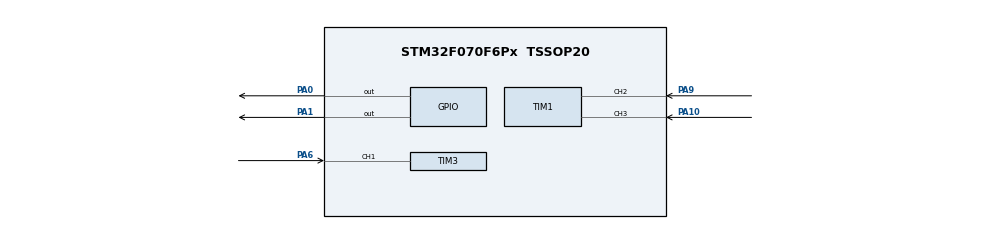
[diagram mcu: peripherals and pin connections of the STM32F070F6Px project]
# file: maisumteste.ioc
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Mcu.Family=STM32F0
Mcu.Name=STM32F070F6Px
Mcu.Package=TSSOP20
NVIC.TIM1_BRK_UP_TRG_COM_IRQn=true\:0\:0\:false\:false\:true\:true\:true\:true
NVIC.TIM1_CC_IRQn=true\:0\:0\:false\:false\:true\:true\:true\:true
NVIC.TIM3_IRQn=true\:0\:0\:false\:false\:true\:true\:true\:true
PA0.Signal=GPIO_Output
PA1.Signal=GPIO_Output
PA10.Signal=S_TIM1_CH3
PA13.Mode=Serial_Wire
PA13.Signal=SYS_SWDIO
PA14.Mode=Serial_Wire
PA14.Signal=SYS_SWCLK
PA6.Signal=S_TIM3_CH1
PA9.Signal=S_TIM1_CH2
PF0-OSC_IN.Mode=HSE-External-Oscillator
PF0-OSC_IN.Signal=RCC_OSC_IN
PF1-OSC_OUT.Mode=HSE-External-Oscillator
PF1-OSC_OUT.Signal=RCC_OSC_OUT
ProjectManager.HeapSize=0x200
ProjectManager.StackSize=0x400
ProjectManager.TargetToolchain=STM32CubeIDE
SH.S_TIM1_CH2.0=TIM1_CH2,Input_Capture2_from_TI2
SH.S_TIM1_CH3.0=TIM1_CH3,Input_Capture3_from_TI3
SH.S_TIM3_CH1.0=TIM3_CH1,Input_Capture1_from_TI1
TIM1.Channel-Input_Capture2_from_TI2=TIM_CHANNEL_2
TIM1.Channel-Input_Capture3_from_TI3=TIM_CHANNEL_3
TIM1.ICPolarity_CH3=TIM_INPUTCHANNELPOLARITY_FALLING
TIM3.Channel-Input_Capture1_from_TI1=TIM_CHANNEL_1
TIM3.Period=1000
TIM3.Prescaler=800
TIM3.TIM_MasterOutputTrigger=TIM_TRGO_RESET
VP_TIM3_VS_ClockSourceINT.Mode=Internal
board=custom

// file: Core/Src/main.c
/* USER CODE BEGIN Header */
/**
  ******************************************************************************
  * @file           : main.c
  * @brief          : Main program body
  ******************************************************************************
  * @attention
  *
  * Copyright (c) 2022 STMicroelectronics.
  * All rights reserved.
  *
  * This software is licensed under terms that can be found in the LICENSE file
  * in the root directory of this software component.
  * If no LICENSE file comes with this software, it is provided AS-IS.
  *
  ******************************************************************************
  */
/* USER CODE END Header */
#include "main.h"

TIM_HandleTypeDef htim1;
TIM_HandleTypeDef htim3;
long uss1_delay = 0;

void SystemClock_Config(void);
static void MX_GPIO_Init(void);
static void MX_TIM3_Init(void);
static void MX_TIM1_Init(void);
/* USER CODE BEGIN PFP */
void HAL_TIM_IC_CaptureCallback(TIM_HandleTypeDef *htim);
void HAL_TIM_PeriodElapsedCallback(TIM_HandleTypeDef *htim);
uint32_t getUs(void);
void Delay_Us(uint32_t micros);
/* USER CODE END PFP */

int main(void)
{

  /* MCU Configuration--------------------------------------------------------*/

  /* Reset of all peripherals, Initializes the Flash interface and the Systick. */
  HAL_Init();

  /* Configure the system clock */
  SystemClock_Config();

  /* Initialize all configured peripherals */
  MX_GPIO_Init();
  MX_TIM3_Init();
  MX_TIM1_Init();
  /* USER CODE BEGIN 2 */
  HAL_TIM_Base_Start_IT(&htim3);//clock do trigger
  HAL_TIM_IC_Start_IT(&htim1, TIM_CHANNEL_2);//pino de subida
  HAL_TIM_IC_Start_IT(&htim1, TIM_CHANNEL_3);//pino de descida
  /* USER CODE END 2 */

  /* Infinite loop */
  while (1)
  {
	  uss1_delay=HAL_TIM_ReadCapturedValue(&htim1, TIM_CHANNEL_3) - HAL_TIM_ReadCapturedValue(&htim1, TIM_CHANNEL_2);
	  HAL_Delay(90);
	  	  if (uss1_delay>600){
	  		  	HAL_GPIO_WritePin(GPIOA,GPIO_PIN_1,GPIO_PIN_SET);
	  	  		HAL_Delay(100);
	  	  		HAL_GPIO_WritePin(GPIOA,GPIO_PIN_1,GPIO_PIN_RESET);
	  	  		HAL_Delay(1000);
	  	  	}
	  	  else if (uss1_delay<=600 && uss1_delay>400){
	  	  	  	HAL_GPIO_WritePin(GPIOA,GPIO_PIN_1,GPIO_PIN_SET);
	  	  	  	HAL_Delay(100);
	  	  	  	HAL_GPIO_WritePin(GPIOA,GPIO_PIN_1,GPIO_PIN_RESET);
	  	  	  	HAL_Delay(500);
	  	  	}
	  	  else if (uss1_delay<=400 && uss1_delay>200){
	  	  		HAL_GPIO_WritePin(GPIOA,GPIO_PIN_1,GPIO_PIN_SET);
	  	  		HAL_Delay(100);
	  	  		HAL_GPIO_WritePin(GPIOA,GPIO_PIN_1,GPIO_PIN_RESET);
	  	  		HAL_Delay(200);
	  	  	}
	  	  else if (uss1_delay<=200 && uss1_delay>100){
	  	  		HAL_GPIO_WritePin(GPIOA,GPIO_PIN_1,GPIO_PIN_SET);
	  	  		HAL_Delay(100);
	  	  		HAL_GPIO_WritePin(GPIOA,GPIO_PIN_1,GPIO_PIN_RESET);
	  	    }
	  	  else if (uss1_delay<=100){
	  			HAL_GPIO_WritePin(GPIOA,GPIO_PIN_1,GPIO_PIN_SET);
	  		}
  }
}

void SystemClock_Config(void)
{
  RCC_OscInitTypeDef RCC_OscInitStruct = {0};
  RCC_ClkInitTypeDef RCC_ClkInitStruct = {0};

  /** Initializes the RCC Oscillators according to the specified parameters
  * in the RCC_OscInitTypeDef structure.
  */
  RCC_OscInitStruct.OscillatorType = RCC_OSCILLATORTYPE_HSI;
  RCC_OscInitStruct.HSIState = RCC_HSI_ON;
  RCC_OscInitStruct.HSICalibrationValue = RCC_HSICALIBRATION_DEFAULT;
  RCC_OscInitStruct.PLL.PLLState = RCC_PLL_NONE;
  if (HAL_RCC_OscConfig(&RCC_OscInitStruct) != HAL_OK)
  {
    Error_Handler();
  }

  /** Initializes the CPU, AHB and APB buses clocks
  */
  RCC_ClkInitStruct.ClockType = RCC_CLOCKTYPE_HCLK|RCC_CLOCKTYPE_SYSCLK
                              |RCC_CLOCKTYPE_PCLK1;
  RCC_ClkInitStruct.SYSCLKSource = RCC_SYSCLKSOURCE_HSI;
  RCC_ClkInitStruct.AHBCLKDivider = RCC_SYSCLK_DIV1;
  RCC_ClkInitStruct.APB1CLKDivider = RCC_HCLK_DIV1;

  if (HAL_RCC_ClockConfig(&RCC_ClkInitStruct, FLASH_LATENCY_0) != HAL_OK)
  {
    Error_Handler();
  }
}

static void MX_TIM1_Init(void)
{

  TIM_MasterConfigTypeDef sMasterConfig = {0};
  TIM_IC_InitTypeDef sConfigIC = {0};

  htim1.Instance = TIM1;
  htim1.Init.Prescaler = 31;
  htim1.Init.CounterMode = TIM_COUNTERMODE_UP;
  htim1.Init.Period = 60000;
  htim1.Init.ClockDivision = TIM_CLOCKDIVISION_DIV1;
  htim1.Init.RepetitionCounter = 0;
  htim1.Init.AutoReloadPreload = TIM_AUTORELOAD_PRELOAD_DISABLE;
  if (HAL_TIM_IC_Init(&htim1) != HAL_OK)
  {
    Error_Handler();
  }
  sMasterConfig.MasterOutputTrigger = TIM_TRGO_RESET;
  sMasterConfig.MasterSlaveMode = TIM_MASTERSLAVEMODE_DISABLE;
  if (HAL_TIMEx_MasterConfigSynchronization(&htim1, &sMasterConfig) != HAL_OK)
  {
    Error_Handler();
  }
  sConfigIC.ICPolarity = TIM_INPUTCHANNELPOLARITY_RISING;
  sConfigIC.ICSelection = TIM_ICSELECTION_DIRECTTI;
  sConfigIC.ICPrescaler = TIM_ICPSC_DIV1;
  sConfigIC.ICFilter = 0;
  if (HAL_TIM_IC_ConfigChannel(&htim1, &sConfigIC, TIM_CHANNEL_2) != HAL_OK)
  {
    Error_Handler();
  }
  sConfigIC.ICPolarity = TIM_INPUTCHANNELPOLARITY_FALLING;
  if (HAL_TIM_IC_ConfigChannel(&htim1, &sConfigIC, TIM_CHANNEL_3) != HAL_OK)
  {
    Error_Handler();
  }

}

static void MX_TIM3_Init(void)
{

  TIM_ClockConfigTypeDef sClockSourceConfig = {0};
  TIM_MasterConfigTypeDef sMasterConfig = {0};
  TIM_IC_InitTypeDef sConfigIC = {0};

  htim3.Instance = TIM3;
  htim3.Init.Prescaler = 800;
  htim3.Init.CounterMode = TIM_COUNTERMODE_UP;
  htim3.Init.Period = 1000;
  htim3.Init.ClockDivision = TIM_CLOCKDIVISION_DIV1;
  htim3.Init.AutoReloadPreload = TIM_AUTORELOAD_PRELOAD_DISABLE;
  if (HAL_TIM_Base_Init(&htim3) != HAL_OK)
  {
    Error_Handler();
  }
  sClockSourceConfig.ClockSource = TIM_CLOCKSOURCE_INTERNAL;
  if (HAL_TIM_ConfigClockSource(&htim3, &sClockSourceConfig) != HAL_OK)
  {
    Error_Handler();
  }
  if (HAL_TIM_IC_Init(&htim3) != HAL_OK)
  {
    Error_Handler();
  }
  sMasterConfig.MasterOutputTrigger = TIM_TRGO_RESET;
  sMasterConfig.MasterSlaveMode = TIM_MASTERSLAVEMODE_DISABLE;
  if (HAL_TIMEx_MasterConfigSynchronization(&htim3, &sMasterConfig) != HAL_OK)
  {
    Error_Handler();
  }
  sConfigIC.ICPolarity = TIM_INPUTCHANNELPOLARITY_RISING;
  sConfigIC.ICSelection = TIM_ICSELECTION_DIRECTTI;
  sConfigIC.ICPrescaler = TIM_ICPSC_DIV1;
  sConfigIC.ICFilter = 0;
  if (HAL_TIM_IC_ConfigChannel(&htim3, &sConfigIC, TIM_CHANNEL_1) != HAL_OK)
  {
    Error_Handler();
  }

}

static void MX_GPIO_Init(void)
{
  GPIO_InitTypeDef GPIO_InitStruct = {0};

  /* GPIO Ports Clock Enable */
  __HAL_RCC_GPIOF_CLK_ENABLE();
  __HAL_RCC_GPIOA_CLK_ENABLE();

  /*Configure GPIO pin Output Level */
  HAL_GPIO_WritePin(GPIOA, GPIO_PIN_0|GPIO_PIN_1, GPIO_PIN_RESET);

  /*Configure GPIO pins : PA0 PA1 */
  GPIO_InitStruct.Pin = GPIO_PIN_0|GPIO_PIN_1;
  GPIO_InitStruct.Mode = GPIO_MODE_OUTPUT_PP;
  GPIO_InitStruct.Pull = GPIO_NOPULL;
  GPIO_InitStruct.Speed = GPIO_SPEED_FREQ_LOW;
  HAL_GPIO_Init(GPIOA, &GPIO_InitStruct);

}

/* USER CODE BEGIN 4
 * */
void HAL_TIM_IC_CaptureCallback(TIM_HandleTypeDef *htim)
{
	if (htim->Instance==TIM1){
		//subida echo uss1
		if(htim->Channel==TIM_CHANNEL_2){

		}
		//descida echo uss1
		if(htim->Channel==TIM_CHANNEL_3){

		}
	}
}

void HAL_TIM_PeriodElapsedCallback(TIM_HandleTypeDef *htim)
{
    if (htim->Instance==TIM3) //
    {
    	//Calcula a largura do pulso de echo do sensor
    	HAL_GPIO_WritePin(GPIOA,GPIO_PIN_0,GPIO_PIN_SET); //USS1 trigger
    	Delay_Us(10);
    	HAL_GPIO_WritePin(GPIOA,GPIO_PIN_0,GPIO_PIN_RESET); //USS1 trigger
    	__HAL_TIM_SET_COUNTER(&htim1,0);
    	//__HAL_TIM_SET_COUNTER(&htim1,0);
    }

}
uint32_t getUs(void) {
	uint32_t usTicks = HAL_RCC_GetSysClockFreq() / 1000000;
	register uint32_t ms, cycle_cnt;
	do {
		ms = HAL_GetTick();
		cycle_cnt = SysTick->VAL;
	} while (ms != HAL_GetTick());

	return (ms * 1000) + (usTicks * 1000 - cycle_cnt) / usTicks;
}

void Delay_Us(uint32_t micros) {
	uint32_t start = getUs();
	while (getUs()-start < (uint32_t) micros);
}
/* USER CODE END 4 */

void Error_Handler(void)
{
  __disable_irq();
  while (1)
  {
  }
}
